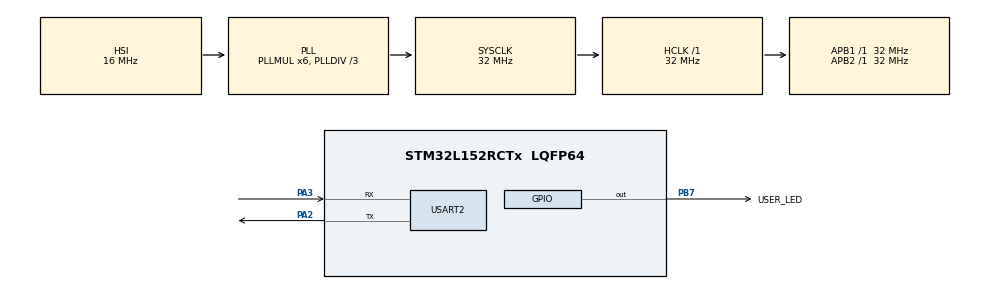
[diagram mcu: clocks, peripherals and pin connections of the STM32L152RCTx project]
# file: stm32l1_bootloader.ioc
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Mcu.Family=STM32L1
Mcu.Name=STM32L152RCTx
Mcu.Package=LQFP64
NVIC.PriorityGroup=NVIC_PRIORITYGROUP_0
PA13.Mode=Serial_Wire
PA13.Signal=SYS_JTMS-SWDIO
PA14.Mode=Serial_Wire
PA14.Signal=SYS_JTCK-SWCLK
PA2.Mode=Asynchronous
PA2.Signal=USART2_TX
PA3.Mode=Asynchronous
PA3.Signal=USART2_RX
PB7.GPIO_Label=USER_LED
PB7.Signal=GPIO_Output
ProjectManager.HeapSize=0x200
ProjectManager.StackSize=0x400
ProjectManager.TargetToolchain=STM32CubeIDE
RCC.48MHZClocksFreq_Value=48000000
RCC.AHBFreq_Value=32000000
RCC.APB1Freq_Value=32000000
RCC.APB1TimFreq_Value=32000000
RCC.APB2Freq_Value=32000000
RCC.APB2TimFreq_Value=32000000
RCC.HCLKFreq_Value=32000000
RCC.HSE_VALUE=8000000
RCC.HSI_VALUE=16000000
RCC.LSE_VALUE=32768
RCC.MSI_VALUE=2097000
RCC.PLLDIV=RCC_PLL_DIV3
RCC.PLLMUL=RCC_PLL_MUL6
RCC.RTCClockSelectionVirtual=RCC_RTCCLKSOURCE_LSE
RCC.SYSCLKFreq_VALUE=32000000
RCC.SYSCLKSource=RCC_SYSCLKSOURCE_PLLCLK
RCC.USBOutput=48000000
RCC.VCOOutputFreq_Value=96000000
USART2.VirtualMode=VM_ASYNC
board=STM32L152C-DISCO

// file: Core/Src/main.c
/* USER CODE BEGIN Header */
/**
  ******************************************************************************
  * @file           : main.c
  * @brief          : Main program body
  ******************************************************************************
  * @attention
  *
  * Copyright (c) 2025 STMicroelectronics.
  * All rights reserved.
  *
  * This software is licensed under terms that can be found in the LICENSE file
  * in the root directory of this software component.
  * If no LICENSE file comes with this software, it is provided AS-IS.
  *
  ******************************************************************************
  */
/* USER CODE END Header */
#include "main.h"

/* USER CODE BEGIN Includes */
#include "stdio.h"
/* USER CODE END Includes */

/* USER CODE BEGIN PM */
typedef void (*ptrF)(uint32_t dlyticks);
typedef void (*pFunction)(void);
/* USER CODE END PM */

UART_HandleTypeDef huart2;

/* USER CODE BEGIN PV */
#ifdef TUTORIAL
unsigned char __attribute__((section(".myBufSectionRAM"))) buf_ram[128];
const unsigned char __attribute__((section(".myBufSectionFLASH"))) buf_flash[10] = {0,1,2,3,4,5,6,7,8,9};
#endif

#define LOCATE_FUNC __attribute__((section(".mysection")))
#define FLASH_APP_ADDR 0x8008000

/* USER CODE END PV */

void SystemClock_Config(void);
static void MX_GPIO_Init(void);
static void MX_USART2_UART_Init(void);
/* USER CODE BEGIN PFP */
int _write(int file, char*ptr, int len);
void LOCATE_FUNC blink(uint32_t delay_tick);
void __attribute__((__section__(".RamFunc"))) TurnOnLED(GPIO_PinState PinState);
#ifdef TUTORIAL
static ptrF Functions[] =
{
		blink
};
#endif
void go2APP(void);

/* USER CODE END PFP */

/* USER CODE BEGIN 0 */
void LOCATE_FUNC blink(uint32_t delay_tick)
{
	HAL_GPIO_TogglePin(USER_LED_GPIO_Port, USER_LED_Pin);
	HAL_Delay(delay_tick);
}

void __attribute__((__section__(".RamFunc"))) TurnOnLED(GPIO_PinState PinState)
{
	if(PinState != GPIO_PIN_RESET)
	{
		USER_LED_GPIO_Port->BSRR = (uint32_t)USER_LED_Pin;
	}
	else
	{
		USER_LED_GPIO_Port->BSRR = (uint32_t)USER_LED_Pin;
	}
}

/*FLASH
0x08004000  +-----------------------------+  ← APP2 tabanı = VTOR değeri
            | VEKTÖR TABLOSU              |  [0] = başlangıç MSP (stack tepe değeri)
            |  - [0] init MSP             |  [1] = Reset_Handler adresi
            |  - [1] Reset_Handler        |  [2..] ISR adresleri
            +-----------------------------+
            | .text  (kod)                |
            | .rodata (const)             |
            | .data'nın FLASH kopyası     |  (resette RAM’e kopyalanır)
            +-----------------------------+
            | (kalan flash)               |
            +-----------------------------+
 * */

/*RAM
0x20008000  +-----------------------------+  ← _estack (MSP’nin başlangıç değeri)
            |           STACK             |  ↓ aşağı doğru büyür
            |  (fonksiyon çağrıları,      |
            |   ISR'ler burada çerçeve     |
            |   açar-kapatır)             |
            +-----------------------------+
            |        serbest alan         |  (stack ↔ heap tampon bölge)
            +-----------------------------+
            |           HEAP              |  ↑ yukarı büyür (malloc/new)
            +-----------------------------+
            | .bss  (sıfırlanır)          |
            | .data (FLASH’tan kopya)     |
0x20000000  +-----------------------------+
 *
 * */

void go2APP(void)
{
	uint32_t jump_address;
	pFunction jump_to_app;
	printf("[SYSTEM]: BOOTLOADER START\r\n");

	// --------------  flash app bolgesinde yuklu bir app var mi diye kontrol ediyoruz --------------------------------
	// ( *(uint32_t*)FLASH_APP_ADDR ) -> vektor tablosundaki ilk word'u okur  yani MSP degerine bakiyoruz
	// MSP degeri RAM'deki stack degerinin tepesini gosteriyor
	// & 0x2FFE0000 -> bu maskelemenin amaci MSP degeri gercekten de RAM'i isaret ediyor mu
	// MSP RAM'i gosteriyorsa -> burada gecerli bir app imaji var (kaba bir kontrol)
	if(  (( *(uint32_t*)FLASH_APP_ADDR ) & 0x2FFE0000) == 0x20000000  )
	{
		printf("[SYSTEM]: APP START\r\n");
		HAL_Delay(100);

			// --------------------app'e atlama----------------------------------------
		jump_address = *(uint32_t*)(FLASH_APP_ADDR + 4); // Reset handler adresini jump_addr olarak tut
		// bu deger reset handler fonksiyonuna dallanacagimiz giris adresi
		// neden buna ziplayacagiz -> cunku reset handler : .data kopyalama, .bss sifirlama, system clocklarini kurmayi halledip main()'e geciren gercek baslangic noktasi
		jump_to_app = (pFunction) jump_address; // artik fonksiyon pointer'la fonksiyonlara erisebilirim

		__set_MSP(*(uint32_t*)(FLASH_APP_ADDR)); // app'in stack pointerini kuruyoruz
		jump_to_app();                           // app'in reset handler'ini cagiriyoruz
	}
	else
	{
		printf("[SYSTEM]: APP NOT FOUND\r\n");
	}
}

int _write(int file, char*ptr, int len)
{
	int data_idx;

	for(data_idx = 0; data_idx < len; data_idx++)
		HAL_UART_Transmit(&huart2, (uint8_t*)ptr++, 1, 100);

	return len;
}
/* USER CODE END 0 */

int main(void)
{

  /* MCU Configuration--------------------------------------------------------*/

  /* Reset of all peripherals, Initializes the Flash interface and the Systick. */
  HAL_Init();

  /* Configure the system clock */
  SystemClock_Config();

  /* Initialize all configured peripherals */
  MX_GPIO_Init();
  MX_USART2_UART_Init();

  /* Infinite loop */
  while (1)
  {

    /* USER CODE BEGIN 3 */
	  //blink(100);
	  //TurnOnLED(0);
#ifdef TUTORIAL
	  (*Functions[0])(100);
#endif
	  go2APP();
  }
  /* USER CODE END 3 */
}

void SystemClock_Config(void)
{
  RCC_OscInitTypeDef RCC_OscInitStruct = {0};
  RCC_ClkInitTypeDef RCC_ClkInitStruct = {0};

  /** Configure the main internal regulator output voltage
  */
  __HAL_PWR_VOLTAGESCALING_CONFIG(PWR_REGULATOR_VOLTAGE_SCALE1);

  /** Initializes the RCC Oscillators according to the specified parameters
  * in the RCC_OscInitTypeDef structure.
  */
  RCC_OscInitStruct.OscillatorType = RCC_OSCILLATORTYPE_HSI;
  RCC_OscInitStruct.HSIState = RCC_HSI_ON;
  RCC_OscInitStruct.HSICalibrationValue = RCC_HSICALIBRATION_DEFAULT;
  RCC_OscInitStruct.PLL.PLLState = RCC_PLL_ON;
  RCC_OscInitStruct.PLL.PLLSource = RCC_PLLSOURCE_HSI;
  RCC_OscInitStruct.PLL.PLLMUL = RCC_PLL_MUL6;
  RCC_OscInitStruct.PLL.PLLDIV = RCC_PLL_DIV3;
  if (HAL_RCC_OscConfig(&RCC_OscInitStruct) != HAL_OK)
  {
    Error_Handler();
  }

  /** Initializes the CPU, AHB and APB buses clocks
  */
  RCC_ClkInitStruct.ClockType = RCC_CLOCKTYPE_HCLK|RCC_CLOCKTYPE_SYSCLK
                              |RCC_CLOCKTYPE_PCLK1|RCC_CLOCKTYPE_PCLK2;
  RCC_ClkInitStruct.SYSCLKSource = RCC_SYSCLKSOURCE_PLLCLK;
  RCC_ClkInitStruct.AHBCLKDivider = RCC_SYSCLK_DIV1;
  RCC_ClkInitStruct.APB1CLKDivider = RCC_HCLK_DIV1;
  RCC_ClkInitStruct.APB2CLKDivider = RCC_HCLK_DIV1;

  if (HAL_RCC_ClockConfig(&RCC_ClkInitStruct, FLASH_LATENCY_1) != HAL_OK)
  {
    Error_Handler();
  }
}

static void MX_USART2_UART_Init(void)
{

  huart2.Instance = USART2;
  huart2.Init.BaudRate = 115200;
  huart2.Init.WordLength = UART_WORDLENGTH_8B;
  huart2.Init.StopBits = UART_STOPBITS_1;
  huart2.Init.Parity = UART_PARITY_NONE;
  huart2.Init.Mode = UART_MODE_TX_RX;
  huart2.Init.HwFlowCtl = UART_HWCONTROL_NONE;
  huart2.Init.OverSampling = UART_OVERSAMPLING_16;
  if (HAL_UART_Init(&huart2) != HAL_OK)
  {
    Error_Handler();
  }

}

static void MX_GPIO_Init(void)
{
  GPIO_InitTypeDef GPIO_InitStruct = {0};

  /* GPIO Ports Clock Enable */
  __HAL_RCC_GPIOA_CLK_ENABLE();
  __HAL_RCC_GPIOB_CLK_ENABLE();

  /*Configure GPIO pin Output Level */
  HAL_GPIO_WritePin(USER_LED_GPIO_Port, USER_LED_Pin, GPIO_PIN_RESET);

  /*Configure GPIO pin : USER_LED_Pin */
  GPIO_InitStruct.Pin = USER_LED_Pin;
  GPIO_InitStruct.Mode = GPIO_MODE_OUTPUT_PP;
  GPIO_InitStruct.Pull = GPIO_NOPULL;
  GPIO_InitStruct.Speed = GPIO_SPEED_FREQ_LOW;
  HAL_GPIO_Init(USER_LED_GPIO_Port, &GPIO_InitStruct);

}

void Error_Handler(void)
{
  __disable_irq();
  while (1)
  {
  }
}
